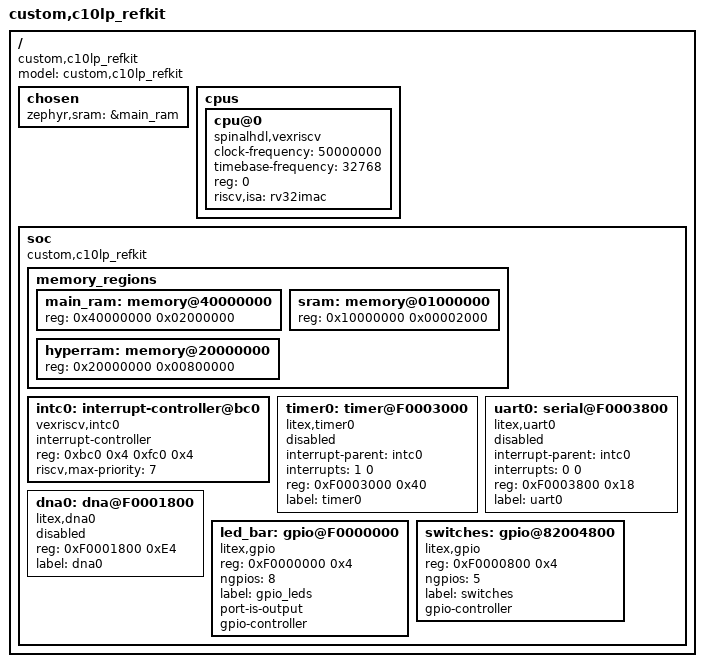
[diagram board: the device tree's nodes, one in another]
/ {

  #address-cells = <1>;
  #size-cells = <1>;
  compatible = "custom,c10lp_refkit";
  model = "custom,c10lp_refkit";

  chosen {
    zephyr,sram = &main_ram;
  };

  cpus {
    #address-cells = <1>;
    #size-cells = <0>;
    cpu@0 {
      clock-frequency = <50000000>;
      timebase-frequency = <32768>;
      compatible = "spinalhdl,vexriscv", "riscv";
      device_type = "cpu";
      reg = <0>;
      riscv,isa = "rv32imac";
      status = "okay";
    };
  };

  soc {
    #address-cells = <1>;
    #size-cells = <1>;
    compatible = "custom,c10lp_refkit";
    ranges;

    memory_regions {
      #address-cells = <1>;
      #size-cells = <1>;

      main_ram: memory@40000000 {
        device_type = "memory";
        reg = <0x40000000 0x02000000>;
      };

      sram: memory@01000000 {
        device_type = "memory";
        reg = <0x10000000 0x00002000>;
      };

      hyperram: memory@20000000 {
        device_type = "memory";
        reg = <0x20000000 0x00800000>;
      };
    };

    intc0: interrupt-controller@bc0 {
      #interrupt-cells = <2>;
      compatible = "vexriscv,intc0";
      interrupt-controller;
      reg = <0xbc0 0x4 0xfc0 0x4>;
      reg-names = "irq_mask", "irq_pending";
      riscv,max-priority = <7>;
    };

    timer0: timer@F0003000 {
      compatible = "litex,timer0";
      interrupt-parent = <&intc0>;
      interrupts = <1 0>;
      reg = <0xF0003000 0x40>;
      reg-names = "control";
      label = "timer0";
      status = "disabled";
    };

    uart0: serial@F0003800 {
      compatible="litex,uart0";
      interrupt-parent = <&intc0>;
      interrupts = <0 0>;
      reg = <0xF0003800 0x18>;
      reg-names = "control";
      label = "uart0";
      status = "disabled";
    };

    dna0: dna@F0001800 {
      compatible = "litex,dna0";
      reg = <0xF0001800 0xE4>;
      reg-names = "mem";
      label = "dna0";
      status = "disabled";
    };

    led_bar: gpio@F0000000 {
      compatible = "litex,gpio";
      reg = <0xF0000000 0x4>;
      reg-names = "control";
      ngpios = <8>;
      label = "gpio_leds";
      port-is-output;
      gpio-controller;
      #gpio-cells = <2>;
      status = "okay";
    };

    switches: gpio@82004800 {
      compatible = "litex,gpio";
      reg = <0xF0000800 0x4>;
      reg-names = "control";
      ngpios = <5>;
      label = "switches";
      gpio-controller;
      #gpio-cells = <2>;
      status = "okay";
    };

  };

};
